# STM32N647 register map
File version: 1.0
CPU: CM55 r0p1, little endian, no MPU, FPU, vendor SysTick, 8 interrupt priority bits
Registers are 32-bit, read-write, reset 0x0 unless marked. A register's access mark holds for its fields unless they carry their own. Offsets are from the block's base; [hi:lo] are bit positions; {n}, {i} and the like mark numbered series.

## RIFSC — Resource isolation framework security controller
Base 0x44024000
Same registers: RIFSC_S 0x54024000
0x00 RISC_CR — RIFSC RISC slave configuration register x
  [0] GLOCK — Global lock
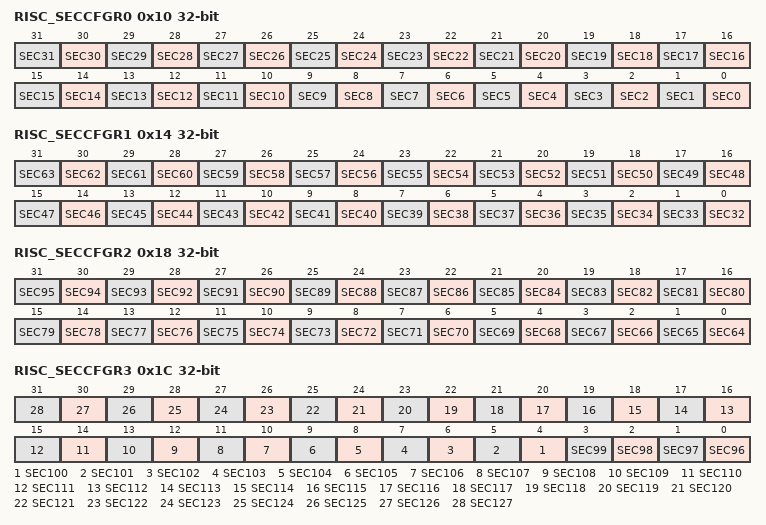
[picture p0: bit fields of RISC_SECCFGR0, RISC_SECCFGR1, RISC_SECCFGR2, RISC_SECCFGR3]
0x10 RISC_SECCFGR0 — RIFSC RISC slave security configuration register 0
  [n] SEC{n} (n=0..31) — security configuration for peripheral {n}
0x14 RISC_SECCFGR1 — RIFSC RISC slave security configuration register 1
  [n-32] SEC{n} (n=32..63) — security configuration for peripheral {n}
0x18 RISC_SECCFGR2 — RIFSC RISC slave security configuration register 2
  [n-64] SEC{n} (n=64..95) — security configuration for peripheral {n}
0x1C RISC_SECCFGR3 — RIFSC RISC slave security configuration register 3
  [n-96] SEC{n} (n=96..127) — security configuration for peripheral {n}
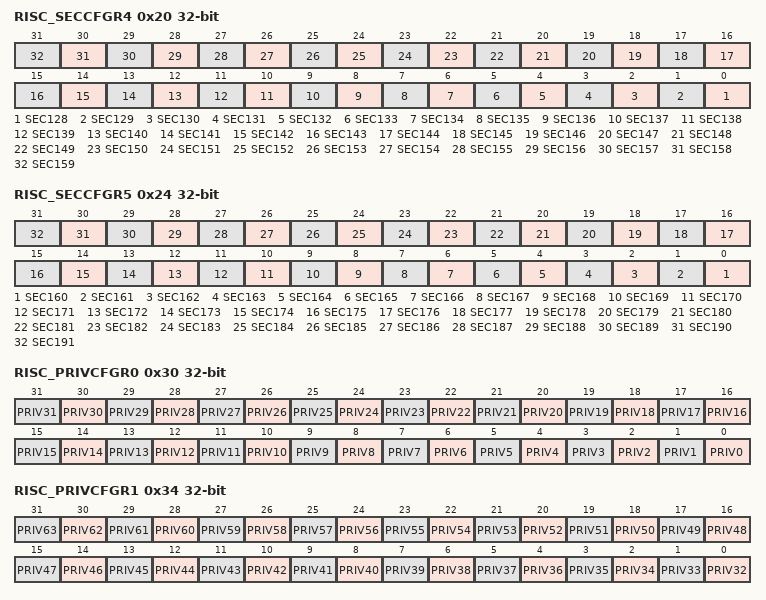
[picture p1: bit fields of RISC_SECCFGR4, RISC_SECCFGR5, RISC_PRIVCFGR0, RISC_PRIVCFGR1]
0x20 RISC_SECCFGR4 — RIFSC RISC slave security configuration register 4
  [n-128] SEC{n} (n=128..159) — security configuration for peripheral {n}
0x24 RISC_SECCFGR5 — RIFSC RISC slave security configuration register 5
  [n-160] SEC{n} (n=160..191) — security configuration for peripheral {n}
0x30 RISC_PRIVCFGR0 — RIFSC RISFC slave privileged register 0
  [n] PRIV{n} (n=0..31) — privileged-only access permission for peripheral {n}
0x34 RISC_PRIVCFGR1 — RIFSC RISFC slave privileged register 1
  [n-32] PRIV{n} (n=32..63) — privileged-only access permission for peripheral {n}
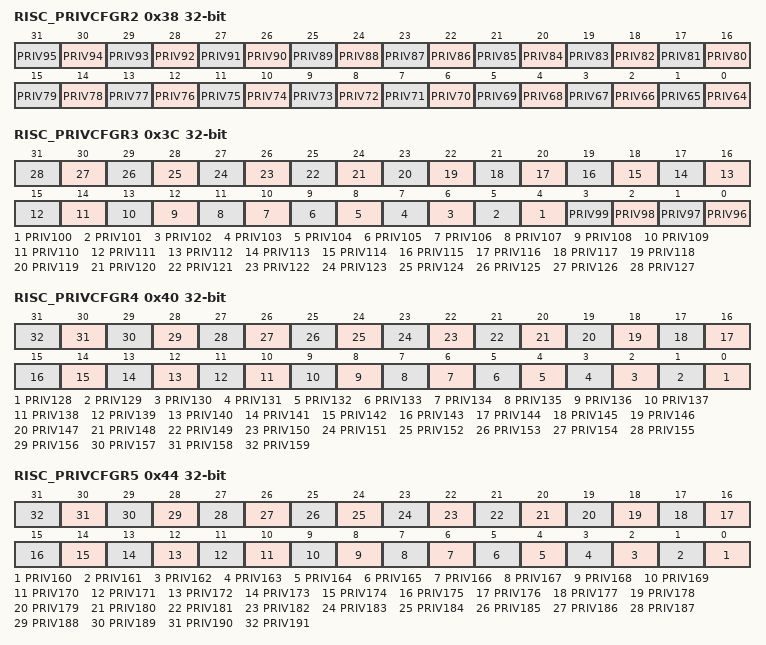
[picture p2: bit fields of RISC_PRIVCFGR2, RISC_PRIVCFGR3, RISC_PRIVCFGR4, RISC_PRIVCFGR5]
0x38 RISC_PRIVCFGR2 — RIFSC RISFC slave privileged register 2
  [n-64] PRIV{n} (n=64..95) — privileged-only access permission for peripheral {n}
0x3C RISC_PRIVCFGR3 — RIFSC RISFC slave privileged register 3
  [n-96] PRIV{n} (n=96..127) — privileged-only access permission for peripheral {n}
0x40 RISC_PRIVCFGR4 — RIFSC RISFC slave privileged register 4
  [n-128] PRIV{n} (n=128..159) — privileged-only access permission for peripheral {n}
0x44 RISC_PRIVCFGR5 — RIFSC RISFC slave privileged register 5
  [n-160] PRIV{n} (n=160..191) — privileged-only access permission for peripheral {n}
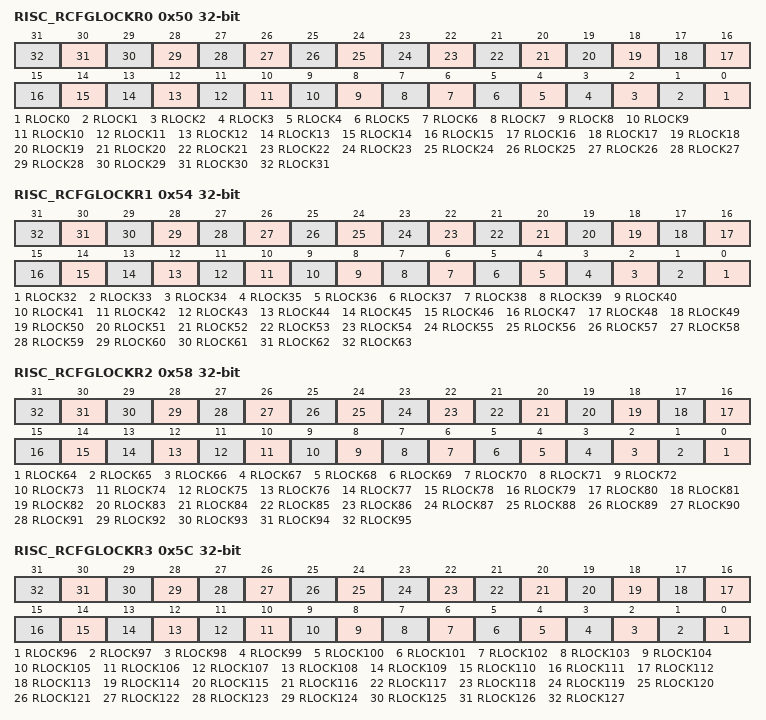
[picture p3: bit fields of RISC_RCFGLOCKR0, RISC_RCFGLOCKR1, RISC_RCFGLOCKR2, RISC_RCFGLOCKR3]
0x50 RISC_RCFGLOCKR0 — RIFSC RISC slave resource configuration lock register 0
  [n] RLOCK{n} (n=0..31) — resource lock for peripheral {n}
0x54 RISC_RCFGLOCKR1 — RIFSC RISC slave resource configuration lock register 1
  [n-32] RLOCK{n} (n=32..63) — resource lock for peripheral {n}
0x58 RISC_RCFGLOCKR2 — RIFSC RISC slave resource configuration lock register 2
  [n-64] RLOCK{n} (n=64..95) — resource lock for peripheral {n}
0x5C RISC_RCFGLOCKR3 — RIFSC RISC slave resource configuration lock register 3
  [n-96] RLOCK{n} (n=96..127) — resource lock for peripheral {n}
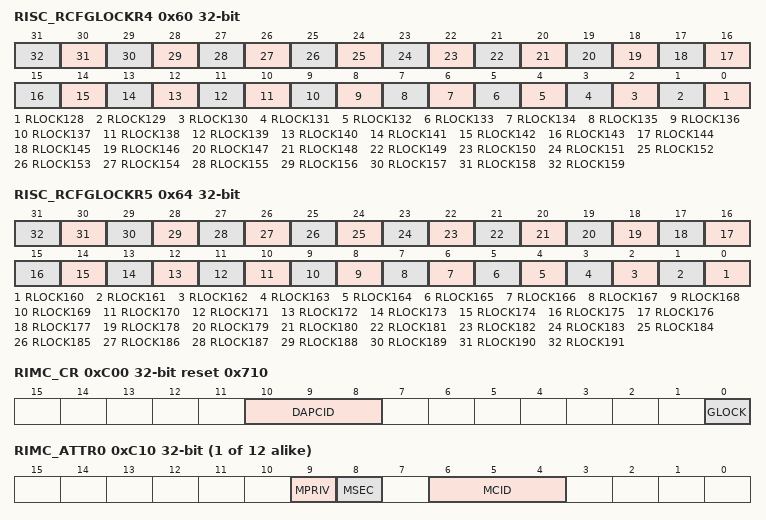
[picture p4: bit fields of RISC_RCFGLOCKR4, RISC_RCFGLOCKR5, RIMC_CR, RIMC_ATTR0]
0x60 RISC_RCFGLOCKR4 — RIFSC RISC slave resource configuration lock register 4
  [n-128] RLOCK{n} (n=128..159) — resource lock for peripheral {n}
0x64 RISC_RCFGLOCKR5 — RIFSC RISC slave resource configuration lock register 5
  [n-160] RLOCK{n} (n=160..191) — resource lock for peripheral {n}
0xC00 RIMC_CR reset 0x710 — RIFSC RIMC master configuration register
  [10:8] DAPCID — debug access port compartment ID
  [0] GLOCK — global lock
{0xC10+4i} RIMC_ATTR{i} (i=0..11) — RIFSC RIMC master attribute register {i}
  [9] MPRIV — master privileged
  [8] MSEC — master secure
  [6:4] MCID — master CID
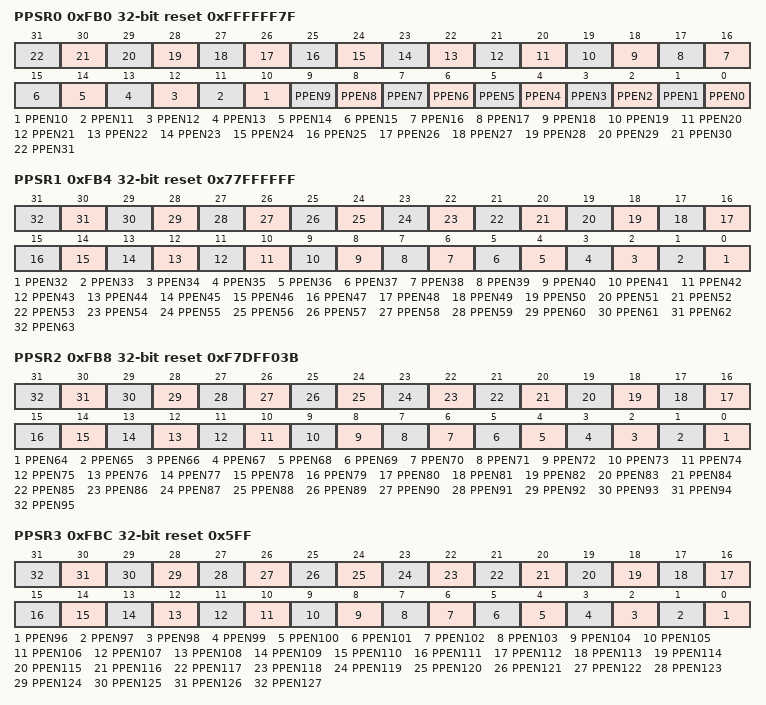
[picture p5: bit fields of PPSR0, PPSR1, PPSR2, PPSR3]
0xFB0 PPSR0 ro reset 0xFFFFFF7F — RIFSC peripheral protection status register 0
  [n] PPEN{n} (n=0..31) — peripheral protection enable {n}
0xFB4 PPSR1 ro reset 0x77FFFFFF — RIFSC peripheral protection status register 1
  [n-32] PPEN{n} (n=32..63) — peripheral protection enable {n}
0xFB8 PPSR2 ro reset 0xF7DFF03B — RIFSC peripheral protection status register 2
  [n-64] PPEN{n} (n=64..95) — peripheral protection enable {n}
0xFBC PPSR3 ro reset 0x5FF — RIFSC peripheral protection status register 3
  [n-96] PPEN{n} (n=96..127) — peripheral protection enable {n}
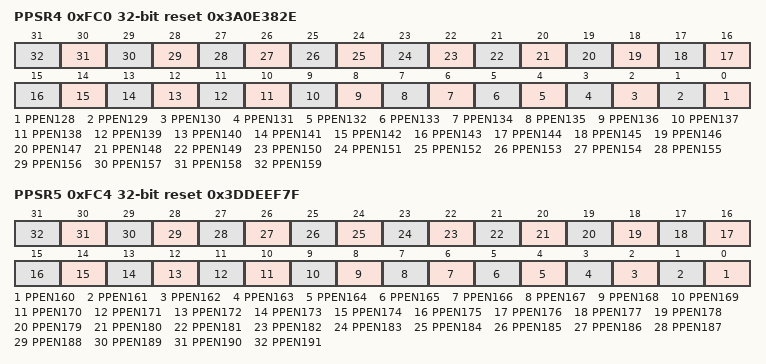
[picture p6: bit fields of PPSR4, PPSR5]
0xFC0 PPSR4 ro reset 0x3A0E382E — RIFSC peripheral protection status register 4
  [n-128] PPEN{n} (n=128..159) — peripheral protection enable {n}
0xFC4 PPSR5 ro reset 0x3DDEEF7F — RIFSC peripheral protection status register 5
  [n-160] PPEN{n} (n=160..191) — peripheral protection enable {n}
